# sam67_dmpac_wrap0_DMPAC_TOP_CFG_SLV_DRU_UTC_DMPAC0_DRU_MMR_CFG_DRU_DRU register map
Vendor: Texas Instruments
Peripheral module from a debugger description file (folder J722S).
Registers are 64-bit, read-only, reset 0x662C0903 unless marked. A register's access mark holds for its fields unless they carry their own. Offsets are as the file gives them; lines under a group give offsets from that group; [hi:lo] are bit positions; {n}, {i} and the like mark numbered series; 'fields as' and 'values as' point back to an identical list; <NAME> marks a mode.

## sam67_dmpac_wrap0_DMPAC_TOP_CFG_SLV_DRU_UTC_DMPAC0_DRU_MMR_CFG_DRU_DRU
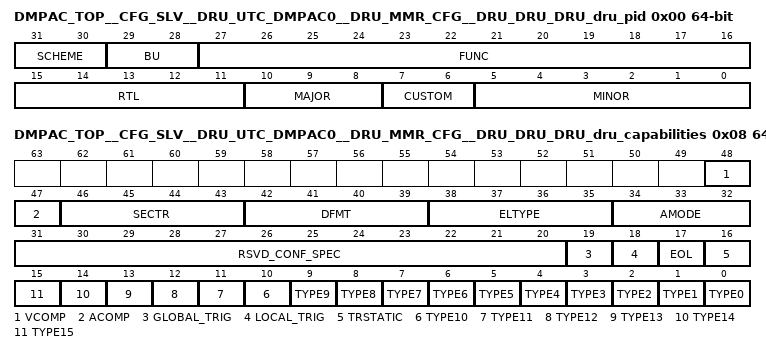
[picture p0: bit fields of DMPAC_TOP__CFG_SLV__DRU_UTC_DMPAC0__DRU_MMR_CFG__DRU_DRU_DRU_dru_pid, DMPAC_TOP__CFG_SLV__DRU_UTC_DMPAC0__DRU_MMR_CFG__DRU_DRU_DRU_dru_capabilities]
0x00 DMPAC_TOP__CFG_SLV__DRU_UTC_DMPAC0__DRU_MMR_CFG__DRU_DRU_DRU_dru_pid — Peripheral ID Register
  [31:30] SCHEME — PID register scheme
  [29:28] BU — Business Unit: 10 = Processors
  [27:16] FUNC — Module ID
  [15:11] RTL — RTL revision. Will vary depending on release.
  [10:8] MAJOR — Major revision
  [7:6] CUSTOM
  [5:0] MINOR — Minor revision
0x08 DMPAC_TOP__CFG_SLV__DRU_UTC_DMPAC0__DRU_MMR_CFG__DRU_DRU_DRU_dru_capabilities reset 0xD9000D0F00 — DRU Capabilities: Lists the capabilities of the channel for TR TYPE and formatting functions
  [48] VCOMP — The DRU supports video compression mode
  [47] ACOMP — The DRU supports analytic compression mode
  [46:43] SECTR — Maximum second TR function that is supported
  [42:39] DFMT — Maximum data reformatting function that is supported
  [38:35] ELTYPE — Maximum element type value that is supported
  [34:32] AMODE — The maximum AMODE that is supported. If AMODE is supported then DIR field must be supported for that AMODE.
  [31:20] RSVD_CONF_SPEC — Reserved for Configuration Specific Features. This implementation has no configuration specific features.
  [19] GLOBAL_TRIG — Global Triggers 0 and 1 are supported
  [18] LOCAL_TRIG — Dedicated Local Trigger is supported
  [17] EOL — EOL Field is supported
  [16] TRSTATIC — STATIC Field is supported
  [n] TYPE{n} (n=0..15) — Type {n} TR is supported
0x40 DMPAC_TOP__CFG_SLV__DRU_UTC_DMPAC0__DRU_MMR_CFG__DRU_DRU_DRU_dru_pri_mask0 rw reset 0x0 — DRU Priority Masks: Enables locking a buffer to be used only by the priority queues
  [n] MASK{n} (n=0..63) — Buffer {n} can only be used by the Priority queue if set to 1.
